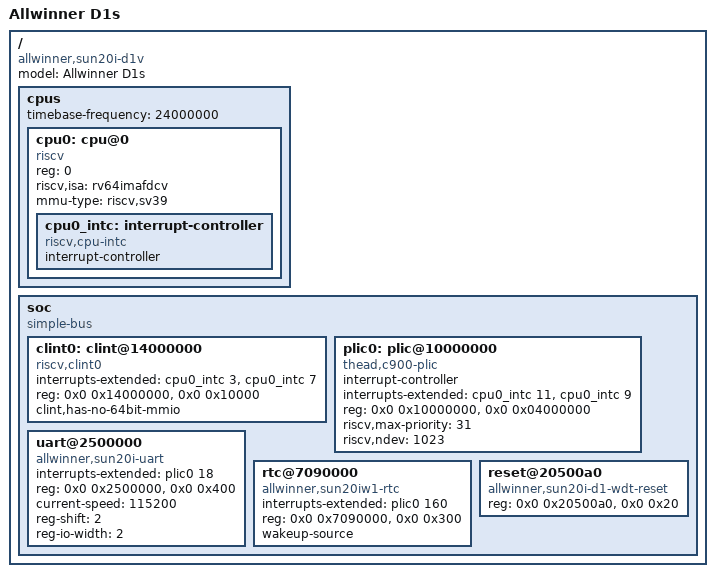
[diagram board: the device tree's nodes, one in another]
/dts-v1/;

/ {
	#address-cells = <2>;
	#size-cells = <2>;
	model = "Allwinner D1s";
	compatible = "allwinner,sun20i-d1v";

	cpus {
		#address-cells = <1>;
		#size-cells = <0>;
		timebase-frequency = <24000000>;
		cpu0: cpu@0 {
			device_type = "cpu";
			reg = <0>;
			status = "okay";
			compatible = "riscv";
			riscv,isa = "rv64imafdcv";
			mmu-type = "riscv,sv39";
			cpu0_intc: interrupt-controller {
				#interrupt-cells = <1>;
				compatible = "riscv,cpu-intc";
				interrupt-controller;
			};
		};
	};

	soc {
		#address-cells = <2>;
		#size-cells = <2>;
		compatible = "simple-bus";
		ranges;

		clint0: clint@14000000 {
			compatible = "riscv,clint0";
			interrupts-extended = <&cpu0_intc 3>, <&cpu0_intc 7>;
			reg = <0x0 0x14000000>, <0x0 0x10000>;
			clint,has-no-64bit-mmio;
		};

		plic0: plic@10000000 {
			#interrupt-cells = <1>;
			compatible = "thead,c900-plic";
			interrupt-controller;
			interrupts-extended = <&cpu0_intc 11>, <&cpu0_intc 9>;
			reg = <0x0 0x10000000>, <0x0 0x04000000>;
			reg-names = "control";
			riscv,max-priority = <31>;
			riscv,ndev = <1023>;
		};

		uart@2500000 {
			compatible = "allwinner,sun20i-uart", "ns16550a";
			interrupts-extended = <&plic0 18>;
			reg = <0x0 0x2500000>, <0x0 0x400>;
			current-speed = <115200>;
			reg-shift = <2>;
			reg-io-width = <2>;
		};

		rtc@7090000 {
			compatible = "allwinner,sun20iw1-rtc";
			interrupts-extended = <&plic0 160>;
			reg = <0x0 0x7090000>, <0x0 0x300>;
			device_type = "rtc";
			wakeup-source;
		};

		reset@20500a0 {
			compatible = "allwinner,sun20i-d1-wdt-reset";
			reg = <0x0 0x20500a0>, <0x0 0x20>;
		};
	};
};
